AUTOSAR XML (schema 323)
package /Cluster
  can cluster CAN
    physical channel CAN
      frame FRAME_CommandModeControl: id 0xFFAB41, frame-length=8, can-addressing-mode=EXTENDED  # Operational commands are received by the module via control bits within this message.
        pdu PDU_CommandModeControl: length=64
          signal Enable_command: start 0, 2 bit, big-endian, data-type=DataType/Enable_command  # Run command. When set to a value of 'Enable', causes transition to grid forming or grid following mode depending on whether AC power is detected. Must be set to 'Disable' to leave POR or FAULTED state.
          signal FaultClear_command: start 2, 2 bit, big-endian, data-type=DataType/FaultClear_command  # Clears the latched fault message.
          signal InvertHwEnable_command: start 56, 2 bit, big-endian, data-type=DataType/InvertHwEnable_command  # Inverts the logic of the Hardware Enable input.
          signal EnableUPSMode_command: start 58, 2 bit, big-endian, data-type=DataType/EnableUPSMode_command  # Enables uninterruptible operation when transitioning from GRID FOLLOWING to GRID FORMING operation. If operating in GRID FOLLOWING mode, and AC grid voltage is interrupted, the module will transition to GRID FORMING mode, with no interruption in power.
          signal EnableSplitPhase_command: start 60, 2 bit, big-endian, data-type=DataType/EnableSplitPhase_command  # Dictates to the module whether it is connected to a three-phase (four wire) or split phase (L1, L2 and N) electrical system.
          signal ForceRelayMX1_command: start 32, 2 bit, big-endian, data-type=DataType/ForceRelayMX1_command  # If set to 'Force On,' will force the relay closed, overriding firmware state machine commands. Meant for diagnostic purposes only.
          signal ForceRelayMX2_command: start 34, 2 bit, big-endian, data-type=DataType/ForceRelayMX2_command  # If set to 'Force On,' will force the relay closed, overriding firmware state machine commands. Meant for diagnostic purposes only.
          signal ForceRelayK1_Precharge_command: start 36, 2 bit, big-endian, data-type=DataType/ForceRelayK1_Precharge_command  # If set to 'Force On,' will force the relay closed, overriding firmware state machine commands. Meant for diagnostic purposes only.
          signal ForceRelayRelayK2_DCRun_comand: start 38, 2 bit, big-endian, data-type=DataType/ForceRelayRelayK2_DCRun_comand  # If set to 'Force On,' will force the relay closed, overriding firmware state machine commands. Meant for diagnostic purposes only.
          signal PhaseRotation_command: start 62, 2 bit, big-endian, data-type=DataType/PhaseRotation_command  # Specifies phase rotation direction. Only active while transitioning from READY to GRID_FORMING
          signal MasterFollowerMode_command: start 16, 2 bit, big-endian, data-type=DataType/MasterFollowerMode_command  # Specifies what power command the inverter will follow in GRID FOLLOWING mode. When configured as Master, CommandPower will be used as the power command. When configured as Slave, the values in StatusMeasuredPower of the master inverter will be used.
      frame FRAME_CommandPower: id 0xCFFAC41, frame-length=8, can-addressing-mode=EXTENDED  # Sets the desired real (P) and reactive (Q) power levels for the module to follow while in the GRID FOLLOWING mode.
        pdu PDU_CommandPower: length=64
          signal RealPower command: start 24, 32 bit, big-endian, data-type=RealPower command  # Commanded real power (W) while in grid following mode - positive real power is defined as power being put into the ac network.
          signal ReactivePower_command: start 56, 32 bit, big-endian, data-type=DataType/ReactivePower_command  # Commanded reactive power (VA) while in grid following mode - positive reactive power is defined as the converter having a leading power factor.
      frame FRAME_CommandVF: id 0xCFFAE41, frame-length=8, can-addressing-mode=EXTENDED  # Sets the desired voltage and frequency for the module to produce while in the GRID FORMING mode. In addition, while in the READY and GRID FOLLOWING modes, this message is used to set the nominal voltage levels for detection of acceptable AC line voltage.
        pdu PDU_CommandVF: length=64
          signal Voltage_command: start 8, 16 bit, big-endian, data-type=DataType/Voltage_command  # Desired output voltage while in grid forming mode.
          signal Frequency_command: start 24, 16 bit, big-endian, data-type=DataType/Frequency_command  # Desired output frequency while in grid forming mode.
      frame FRAME_MasterMeasuredPower: id 0xCFFCAF6, frame-length=8, can-addressing-mode=EXTENDED  # Returns the actual measured power.
        pdu PDU_MasterMeasuredPower: length=64
          signal RealPower_measured: start 24, 32 bit, big-endian, data-type=DataType/RealPower_measured  # Measured real power.
          signal ReactivePower_measured: start 56, 32 bit, big-endian, data-type=DataType/ReactivePower_measured  # Measured reactive power.
      frame FRAME_CommandFactoryControl: id 0xCFFAF41, frame-length=8, can-addressing-mode=EXTENDED
        pdu PDU_CommandFactoryControl: length=64
          signal WriteSerialNumber: start 0, 2 bit, big-endian, data-type=WriteSerialNumber
          signal SerialNumber: start 56, 32 bit, big-endian, data-type=DataType/SerialNumber  # Serial number of the power module.
          signal FactoryAccess: start 24, 16 bit, big-endian, data-type=FactoryAccess
      frame FRAME_CommandSetNVParam: id 0xCFFAA41, frame-length=8, can-addressing-mode=EXTENDED  # Provides access to configure non-volatile parameters. Note that these parameters can only be set when the inverter's power stage is disabled (PowerCircuitEnabled_status in StatusBits message is 'Disabled.')
        pdu PDU_CommandSetNVParam: length=64
          signal CommandSetNVParam_MUX: start 8, 16 bit, big-endian, data-type=CommandSetNVParam_MUX
          signal Dummy: start 24, 16 bit, big-endian, data-type=DataType/Dummy
          signal VUnder50pct: start 24, 16 bit, big-endian, data-type=DataType/VUnder50pct
          signal V50to88pct: start 40, 16 bit, big-endian, data-type=DataType/V50to88pct
          signal V110to120pct: start 56, 16 bit, big-endian, data-type=DataType/V110to120pct
          signal VOver120: start 24, 16 bit, big-endian, data-type=DataType/VOver120
          signal FreqHi: start 24, 16 bit, big-endian, data-type=DataType/FreqHi
          signal FreqLo: start 40, 16 bit, big-endian, data-type=DataType/FreqLo
          signal FreqVeryLo: start 56, 16 bit, big-endian, data-type=DataType/FreqVeryLo
          signal FreqVeryLo: start 24, 16 bit, big-endian, data-type=DataType/FreqVeryLo
          signal FreqLo: start 40, 16 bit, big-endian, data-type=DataType/FreqLo
          signal FreqHi: start 56, 16 bit, big-endian, data-type=DataType/FreqHi
          signal NodeID: start 16, 8 bit, big-endian, data-type=NodeID  # J1939 Source Address node for the module.
          signal SA_Mask: start 24, 8 bit, big-endian, data-type=SA_Mask  # Not presently used.
          signal Baudrate: start 36, 4 bit, big-endian, data-type=Baudrate  # CAN baudrate
          signal ThermalOverload: start 16, 2 bit, big-endian, data-type=DataType/ThermalOverload
          signal MX1Open: start 24, 16 bit, big-endian, data-type=MX1Open  # Maximum time required for the MX1 contactor to open.
          signal MX1Close: start 40, 16 bit, big-endian, data-type=MX1Close  # Maximum time required for the MX1 contactor to close.
          signal MX2Open: start 56, 16 bit, big-endian, data-type=MX2Open  # Maximum time required for the MX2 contactor to open.
          signal MX2Close: start 24, 16 bit, big-endian, data-type=MX2Close  # Maximum time required for the MX2 contactor to open.
          signal K1Open: start 40, 16 bit, big-endian, data-type=K1Open  # Maximum time required for the K1 contactor to open.
          signal K1Close: start 56, 16 bit, big-endian, data-type=K1Close  # Maximum time required for the K1 contactor to close.
          signal K2Open: start 24, 16 bit, big-endian, data-type=K2Open  # Maximum time required for the K2 contactor to open.
          signal K2Close: start 40, 16 bit, big-endian, data-type=K2Close  # Maximum time required for the K2 contactor to close.
      frame FRAME_CommandModeControlAPU2: id 0xFF9B41, frame-length=8, can-addressing-mode=EXTENDED  # Operational commands are received by the module via control bits within this message.
        pdu PDU_CommandModeControlAPU2: length=64
          signal Enable_command: start 0, 2 bit, big-endian, data-type=DataType/Enable_command  # Run command. When set to a value of 'Enable', causes transition to grid forming or grid following mode depending on whether AC power is detected. Must be set to 'Disable' to leave POR or FAULTED state.
          signal FaultClear_command: start 2, 2 bit, big-endian, data-type=DataType/FaultClear_command  # Clears the latched fault message.
          signal InvertHwEnable_command: start 56, 2 bit, big-endian, data-type=DataType/InvertHwEnable_command  # Inverts the logic of the Hardware Enable input.
          signal EnableUPSMode_command: start 58, 2 bit, big-endian, data-type=DataType/EnableUPSMode_command  # Enables uninterruptible operation when transitioning from GRID FOLLOWING to GRID FORMING operation. If operating in GRID FOLLOWING mode, and AC grid voltage is interrupted, the module will transition to GRID FORMING mode, with no interruption in power.
          signal EnableSplitPhase_command: start 60, 2 bit, big-endian, data-type=DataType/EnableSplitPhase_command  # Dictates to the module whether it is connected to a three-phase (four wire) or split phase (L1, L2 and N) electrical system.
          signal ForceRelayMX1_command: start 32, 2 bit, big-endian, data-type=DataType/ForceRelayMX1_command  # If set to 'Force On,' will force the relay closed, overriding firmware state machine commands. Meant for diagnostic purposes only.
          signal ForceRelayMX2_command: start 34, 2 bit, big-endian, data-type=DataType/ForceRelayMX2_command  # If set to 'Force On,' will force the relay closed, overriding firmware state machine commands. Meant for diagnostic purposes only.
          signal ForceRelayK1_Precharge_command: start 36, 2 bit, big-endian, data-type=DataType/ForceRelayK1_Precharge_command  # If set to 'Force On,' will force the relay closed, overriding firmware state machine commands. Meant for diagnostic purposes only.
          signal ForceRelayRelayK2_DCRun_comand: start 38, 2 bit, big-endian, data-type=DataType/ForceRelayRelayK2_DCRun_comand  # If set to 'Force On,' will force the relay closed, overriding firmware state machine commands. Meant for diagnostic purposes only.
          signal PhaseRotation_command: start 62, 2 bit, big-endian, data-type=DataType/PhaseRotation_command  # Specifies phase rotation direction. Only active while transitioning from READY to GRID_FORMING
          signal MasterFollowerMode_command: start 16, 2 bit, big-endian, data-type=DataType/MasterFollowerMode_command  # Specifies what power command the inverter will follow in GRID FOLLOWING mode. When configured as Master, CommandPower will be used as the power command. When configured as Slave, the values in StatusMeasuredPower of the master inverter will be used.
      frame FRAME_CommandPowerAPU2: id 0xCFF9C41, frame-length=8, can-addressing-mode=EXTENDED  # Sets the desired real (P) and reactive (Q) power levels for the module to follow while in the GRID FOLLOWING mode.
        pdu PDU_CommandPowerAPU2: length=64
          signal RealPower_command: start 24, 32 bit, big-endian, data-type=RealPower_command  # Commanded real power (W) while in grid following mode - positive real power is defined as power being put into the ac network.
          signal ReactivePower_command: start 56, 32 bit, big-endian, data-type=DataType/ReactivePower_command  # Commanded reactive power (VA) while in grid following mode - positive reactive power is defined as the converter having a leading power factor.
      frame FRAME_CommandVFAPU2: id 0xCFF9E41, frame-length=8, can-addressing-mode=EXTENDED  # Sets the desired voltage and frequency for the module to produce while in the GRID FORMING mode. In addition, while in the READY and GRID FOLLOWING modes, this message is used to set the nominal voltage levels for detection of acceptable AC line voltage.
        pdu PDU_CommandVFAPU2: length=64
          signal Voltage_command: start 8, 16 bit, big-endian, data-type=DataType/Voltage_command  # Desired output voltage while in grid forming mode.
          signal Frequency_command: start 24, 16 bit, big-endian, data-type=DataType/Frequency_command  # Desired output frequency while in grid forming mode.
      frame FRAME_MasterMeasuredPowerAPU2: id 0xCFFCAF7, frame-length=8, can-addressing-mode=EXTENDED  # Returns the actual measured power.
        pdu PDU_MasterMeasuredPowerAPU2: length=64
          signal RealPower_measured: start 24, 32 bit, big-endian, data-type=DataType/RealPower_measured  # Measured real power.
          signal ReactivePower_measured: start 56, 32 bit, big-endian, data-type=DataType/ReactivePower_measured  # Measured reactive power.
      frame FRAME_justString: id 0x1CFFACC0, frame-length=8, can-addressing-mode=EXTENDED
        pdu PDU_justString: length=64
      frame FRAME_stringAndOther: id 0x1CFFABC0, frame-length=8, can-addressing-mode=EXTENDED
        pdu PDU_stringAndOther: length=64
          signal RealPower_measured: start 24, 32 bit, big-endian, data-type=DataType/RealPower_measured  # Measured real power.
      frame FRAME_StatusMeasuredPower: id 0xCFFCAF7, frame-length=8, can-addressing-mode=EXTENDED  # Returns the actual measured power.
        pdu PDU_StatusMeasuredPower: length=64
          signal RealPower_measured: start 24, 32 bit, big-endian, data-type=DataType/RealPower_measured  # Measured real power.
          signal ReactivePower_measured: start 56, 32 bit, big-endian, data-type=DataType/ReactivePower_measured  # Measured reactive power.
      frame FRAME_StatusCommandedPower: id 0x18FFC4F7, frame-length=8, can-addressing-mode=EXTENDED  # Echoes the commanded power (P&Q) as received in CommandPQ.
        pdu PDU_StatusCommandedPower: length=64
          signal RealPower_echo: start 24, 32 bit, big-endian, data-type=RealPower_echo  # Echoed real power command.
          signal ReactivePower_echo: start 56, 32 bit, big-endian, data-type=ReactivePower_echo  # Echoed reactive power command.
      frame FRAME_StatusBits: id 0xCFFC3F7, frame-length=8, can-addressing-mode=EXTENDED  # Bits representing the status of the power module.
        pdu PDU_StatusBits: length=64
          signal State_status: start 0, 4 bit, big-endian, data-type=State_status  # Active control mode.
          signal MX2Permissive_status: start 18, 2 bit, big-endian, data-type=MX2Permissive_status  # MX2 relay status
          signal PowerAvailAC_status: start 10, 2 bit, big-endian, data-type=PowerAvailAC_status  # Indicates that AC power is connected and that voltage and frequency are within nominal ranges.
          signal PowerAvailDC_status: start 12, 2 bit, big-endian, data-type=PowerAvailDC_status  # Indicates that DC bus voltage is within operating range.
          signal PowerCircuitEnabled_status: start 14, 2 bit, big-endian, data-type=PowerCircuitEnabled_status  # Indicates whether the switching devices are active.
          signal HardwareEnable_status: start 8, 2 bit, big-endian, data-type=HardwareEnable_status  # Status of the hardware enable.
          signal Enable_echo: start 4, 2 bit, big-endian, data-type=Enable_echo  # Echos the state of the Enable command withing the CommandModeControl message.
          signal FaultClr_echo: start 6, 2 bit, big-endian, data-type=FaultClr_echo  # Echos the state of the FaultClear command withing the CommandModeControl message.
          signal MessageValidModeControl_status: start 24, 2 bit, big-endian, data-type=MessageValidModeControl_status  # Indicates the validity of the CommandModeControl message. Message must be received at least once per second and parameter data within range to be considered valid.
          signal MX1Permissive_status: start 16, 2 bit, big-endian, data-type=MX1Permissive_status  # MX1 relay status
          signal K2DCRunPermissive_status: start 22, 2 bit, big-endian, data-type=K2DCRunPermissive_status  # K2 DC Run relay status.
          signal K1PrechargePermissive_status: start 20, 2 bit, big-endian, data-type=K1PrechargePermissive_status  # K1 precharge relay status.
          signal MessageValidPowerCMD_status: start 26, 2 bit, big-endian, data-type=MessageValidPowerCMD_status  # Indicates the validity of the CommandPQ message. Message must be received at least once per second and parameter data within range to be considered valid.
          signal MessageValidVF_status: start 28, 2 bit, big-endian, data-type=MessageValidVF_status  # Indicates the validity of the CommandVF message. Message must be received at least once per second and parameter data within range to be considered valid.
          signal CANbus_status: start 30, 2 bit, big-endian, data-type=CANbus_status  # Operational status of the CAN bus driver.
          signal EnableUPSMode_echo: start 32, 2 bit, big-endian, data-type=EnableUPSMode_echo  # Echos the state of the EnableUPSMode command withing the CommandModeControl message.
          signal EnableSplitPhase_echo: start 34, 2 bit, big-endian, data-type=EnableSplitPhase_echo  # Echos the state of the EnableSplitPhase command withing the CommandModeControl message.
          signal PhaseRotation_status: start 36, 2 bit, big-endian, data-type=PhaseRotation_status  # Phase rotation order. When L1 phase angle leads L2 phase angle, rotation is considered positive.
          signal LineVoltageDetected_status: start 38, 2 bit, big-endian, data-type=LineVoltageDetected_status  # Flag indicating if voltage is detected on L1, L2 or L3.
          signal PhaseRotation_echo: start 40, 2 bit, big-endian, data-type=PhaseRotation_echo  # Echos the state of PhaseRotation_command withing the CommandModeControl message.
      frame FRAME_StatusControlVoltage: id 0x1CFFC5F7, frame-length=8, can-addressing-mode=EXTENDED  # Lists present voltage of each power supply on the control board (24V, 15V, 5V, and 3.3V.)
        pdu PDU_StatusControlVoltage: length=64
          signal v5p0_Supply: start 8, 16 bit, big-endian, data-type=v5p0_Supply  # Present voltage of the control board 5V power suppy.
          signal v3p3_Supply: start 24, 16 bit, big-endian, data-type=v3p3_Supply  # Present voltage of the control board 3.3V power supply.
          signal v24_Supply: start 40, 16 bit, big-endian, data-type=v24_Supply  # Present voltage of the control board 24V power supply.
          signal v15_Supply: start 56, 16 bit, big-endian, data-type=v15_Supply  # Present voltage of the control board 15V power supply.
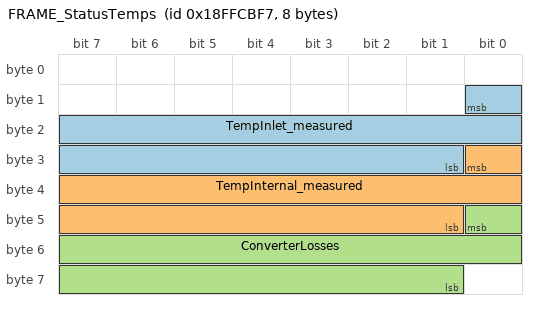
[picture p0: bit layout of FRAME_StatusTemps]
      frame FRAME_StatusTemps: id 0x18FFCBF7, frame-length=8, can-addressing-mode=EXTENDED  # Returns the inlet water temperature to the module as well as module internal ambient temperature.
        pdu PDU_StatusTemps: length=64
          signal TempInlet_measured: start 8, 16 bit, big-endian, data-type=TempInlet_measured  # Coolant inlet temperature
          signal TempInternal_measured: start 24, 16 bit, big-endian, data-type=TempInternal_measured  # Internal ambient temperature
          signal ConverterLosses: start 40, 16 bit, big-endian, data-type=ConverterLosses  # Power converter thermal loss
      frame FRAME_StatusFaults: id 0xCFFC8F7, frame-length=8, can-addressing-mode=EXTENDED  # Fault bits.
        pdu PDU_StatusFaults: length=64
          signal BridgeAVoltageOk_status: start 59, 1 bit, big-endian, data-type=BridgeAVoltageOk_status  # Indicates whether a hardware trip has been activated.
          signal OvercurrentAC_status: start 2, 2 bit, big-endian, data-type=OvercurrentAC_status  # Set immediately upon the software detection of AC current exceeding the threshold value.
          signal BridgeBVoltageOk_status: start 43, 1 bit, big-endian, data-type=BridgeBVoltageOk_status  # Indicates whether a hardware trip has been activated.
          signal OvervoltageDC_status: start 8, 2 bit, big-endian, data-type=OvervoltageDC_status  # Set immediately upon the software detection of DC voltage exceeding the threshold value.
          signal OvertempPowerDevice_status: start 14, 2 bit, big-endian, data-type=OvertempPowerDevice_status  # Set immediately upon the software detection of an IGBT temperature exceeding the threshold value.
          signal OvertempInternal_status: start 12, 2 bit, big-endian, data-type=OvertempInternal_status  # Set immediately upon the software detection of an internal inverter temperature exceeding the threshold value.
          signal LossValidControlMessage_status: start 20, 4 bit, big-endian, data-type=LossValidControlMessage_status  # Set whenever a control message required for operation contains out of range data or has not been received within the required timeout period.
          signal UndervoltageDC_status: start 10, 2 bit, big-endian, data-type=UndervoltageDC_status  # Indicates loss of DC source voltage.
          signal ControlHardwareFail_status: start 16, 4 bit, big-endian, data-type=ControlHardwareFail_status  # Set upon the failure of control hardware to return expected response.
          signal OvercurrentDC_status: start 6, 2 bit, big-endian, data-type=OvercurrentDC_status  # Set immediately upon the software detection of DC current exceeding the threshold value.
          signal GeneralFault_status: start 0, 2 bit, big-endian, data-type=GeneralFault_status  # Will be set any time a fault shutdown has occurred. It is always accompanied by an additional fault descriptor.
          signal LossOfAC_status: start 4, 2 bit, big-endian, data-type=LossOfAC_status  # In grid following mode, this fault will be triggered if AC voltage or frequency goes outside of nominal bounds and EnableUPSMode is not set in the CommandModeControl message.
          signal EStopShutdown_status: start 24, 2 bit, big-endian, data-type=EStopShutdown_status  # Set when an enable request has been sent whithout the WakeUpSignal flag (hardware enable) in the StatusBits message being active.
          signal BridgeAFault_status: start 56, 3 bit, big-endian, data-type=BridgeAFault_status  # Each bridge has hardware protection features as a backup to software protection. This bitfield indicates which, if any of these protection trips is active.
          signal BridgeBFault_status: start 40, 3 bit, big-endian, data-type=BridgeBFault_status  # Each bridge has hardware protection features as a backup to software protection. This bitfield indicates which, if any of these protection trips is active.
          signal IllegalTransition_status: start 26, 2 bit, big-endian, data-type=IllegalTransition_status  # Indicates that an illegal state transition was requested. For example, this fault will occur if Enable is commanded and line voltage is detected but AC power is not available.
          signal InvalidEEHeader_status: start 28, 2 bit, big-endian, data-type=InvalidEEHeader_status  # Indicates that reading of non-volatile parameters at power-up failed.
          signal InvalidEESection_status: start 30, 2 bit, big-endian, data-type=InvalidEESection_status  # Indicates that reading or writing of an non-volatile parameter section failed.
          signal ThermalOverload: start 32, 2 bit, big-endian, data-type=DataType/ThermalOverload
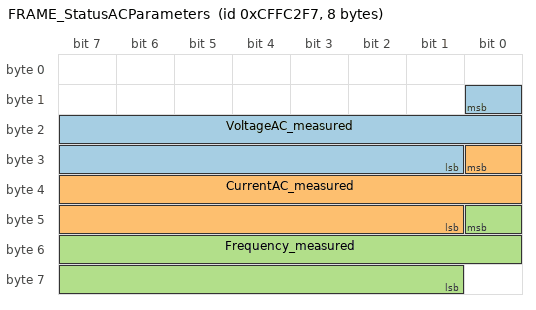
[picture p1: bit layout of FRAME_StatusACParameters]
      frame FRAME_StatusACParameters: id 0xCFFC2F7, frame-length=8, can-addressing-mode=EXTENDED  # RMS AC Voltage, current, and frequency measured by line A, B and C feedbacks.
        pdu PDU_StatusACParameters: length=64
          signal VoltageAC_measured: start 8, 16 bit, big-endian, data-type=VoltageAC_measured  # Measured RMS AC voltage.
          signal CurrentAC_measured: start 24, 16 bit, big-endian, data-type=CurrentAC_measured  # Measured RMS AC current.
          signal Frequency_measured: start 40, 16 bit, big-endian, data-type=Frequency_measured  # Measured frequency.
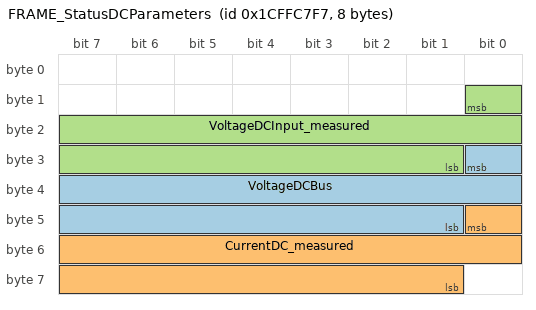
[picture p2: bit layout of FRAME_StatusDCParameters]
      frame FRAME_StatusDCParameters: id 0x1CFFC7F7, frame-length=8, can-addressing-mode=EXTENDED  # Measured (boosted) DC Bus voltage, DC Current, and estimated DC Input voltage.
        pdu PDU_StatusDCParameters: length=64
          signal VoltageDCBus: start 24, 16 bit, big-endian, data-type=VoltageDCBus  # Measured DC bus voltage.
          signal CurrentDC_measured: start 40, 16 bit, big-endian, data-type=CurrentDC_measured  # Measured DC current.
          signal VoltageDCInput_measured: start 8, 16 bit, big-endian, data-type=VoltageDCInput_measured  # Estimated DC input voltage.
      frame FRAME_StatusControlVolts2: id 0x1CFFC6F7, frame-length=8, can-addressing-mode=EXTENDED  # Present voltage of the -15V power supply on the control board.
        pdu PDU_StatusControlVolts2: length=64
          signal n15V_Supply: start 8, 16 bit, big-endian, data-type=n15V_Supply  # Present voltage of the control board -15V power supply.
          signal DiodeTemperature: start 40, 16 bit, big-endian, data-type=DiodeTemperature  # Hottest diode
          signal IGBTTemperature: start 56, 16 bit, big-endian, data-type=IGBTTemperature  # Hottest IGBT
      frame FRAME_softwareRev: id 0x1CFFC1F7, frame-length=8, can-addressing-mode=EXTENDED  # Software revision.
        pdu PDU_softwareRev: length=64
          signal InterfaceRev: start 24, 16 bit, big-endian, data-type=InterfaceRev  # Software revision of the CAN communication interface.
          signal ControlSwRev: start 8, 16 bit, big-endian, data-type=ControlSwRev  # Software revision of the control firmware.
          signal BuildTime: start 56, 32 bit, big-endian, data-type=BuildTime  # Build timestamp.
      frame FRAME_StatusCommandVF: id 0x18FFC9F7, frame-length=8, can-addressing-mode=EXTENDED  # Echoes the voltage and frequency commands from commandVF.
        pdu PDU_StatusCommandVF: length=64
          signal Voltage_echo: start 8, 16 bit, big-endian, data-type=Voltage_echo  # Echoed voltage command
          signal Frequency_echo: start 24, 16 bit, big-endian, data-type=Frequency_echo  # Echoed frequency command.
      frame FRAME_serialNumber: id 0x1CFFCCF7, frame-length=8, can-addressing-mode=EXTENDED  # Serial number of the power module.
        pdu PDU_serialNumber: length=64
          signal SerialNumber: start 24, 32 bit, big-endian, data-type=DataType/SerialNumber  # Serial number of the power module.
      frame FRAME_softwareRevHash: id 0x1CFFCDF7, frame-length=8, can-addressing-mode=EXTENDED  # Unique software revision identification hashcode.
        pdu PDU_softwareRevHash: length=64
          signal Hash: start 28, 28 bit, big-endian, data-type=Hash  # Unique revision identification hashcode.
      frame FRAME_StatusNVParam: id 0x1CFFA9F7, frame-length=8, can-addressing-mode=EXTENDED  # Echos back parameter values.
        pdu PDU_StatusNVParam: length=64
          signal StatusNVParam_MUX: start 8, 16 bit, big-endian, data-type=StatusNVParam_MUX
          signal Dummy: start 24, 16 bit, big-endian, data-type=DataType/Dummy
          signal VUnder50pct: start 24, 16 bit, big-endian, data-type=DataType/VUnder50pct
          signal V50to88pct: start 40, 16 bit, big-endian, data-type=DataType/V50to88pct
          signal V110to120pct: start 56, 16 bit, big-endian, data-type=DataType/V110to120pct
          signal VOver120: start 24, 16 bit, big-endian, data-type=DataType/VOver120
          signal FreqHi: start 24, 16 bit, big-endian, data-type=DataType/FreqHi
          signal FreqLo: start 40, 16 bit, big-endian, data-type=DataType/FreqLo
          signal FreqVeryLo: start 56, 16 bit, big-endian, data-type=DataType/FreqVeryLo
          signal FreqVeryLo: start 24, 16 bit, big-endian, data-type=DataType/FreqVeryLo
          signal FreqLo: start 40, 16 bit, big-endian, data-type=DataType/FreqLo
          signal FreqHi: start 56, 16 bit, big-endian, data-type=DataType/FreqHi
          signal StatusNodeID: start 16, 8 bit, big-endian, data-type=StatusNodeID  # J1939 Source Address node for the module
          signal StatusSA_Mask: start 24, 8 bit, big-endian, data-type=StatusSA_Mask  # Mask used to configure from which master source addresses to accept commands.
          signal StatusBaudrate: start 36, 4 bit, big-endian, data-type=StatusBaudrate
          signal StatusThermalOverload: start 16, 2 bit, big-endian, data-type=StatusThermalOverload  # Configured action to take when thermal overload input is active.
          signal StatusMX1Open: start 24, 16 bit, big-endian, data-type=StatusMX1Open  # Maximum time required for the MX1 contactor to open.
          signal StatusMX1Close: start 40, 16 bit, big-endian, data-type=StatusMX1Close  # Maximum time required for the MX1 contactor to close.
          signal StatusMX2Open: start 56, 16 bit, big-endian, data-type=StatusMX2Open  # Maximum time required for the MX2 contactor to open.
          signal StatusMX2Close: start 24, 16 bit, big-endian, data-type=StatusMX2Close  # Maximum time required for the MX2 contactor to open.
          signal StatusK1Open: start 40, 16 bit, big-endian, data-type=StatusK1Open  # Maximum time required for the K1 contactor to open.
          signal StatusK1Close: start 56, 16 bit, big-endian, data-type=StatusK1Close  # Maximum time required for the K1 contactor to close.
          signal StatusK2Open: start 24, 16 bit, big-endian, data-type=StatusK2Open  # Maximum time required for the K2 contactor to open.
          signal StatusK2Close: start 40, 16 bit, big-endian, data-type=StatusK2Close  # Maximum time required for the K2 contactor to close.
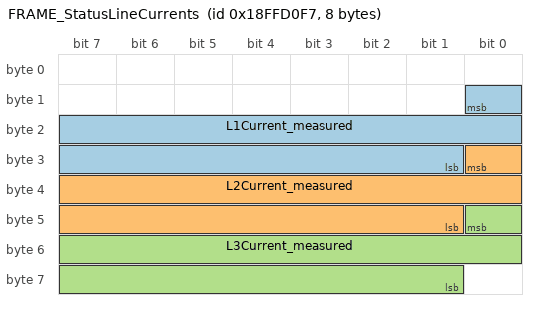
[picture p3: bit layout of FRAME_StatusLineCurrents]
      frame FRAME_StatusLineCurrents: id 0x18FFD0F7, frame-length=8, can-addressing-mode=EXTENDED  # Measured RMS line currents.
        pdu PDU_StatusLineCurrents: length=64
          signal L1Current_measured: start 8, 16 bit, big-endian, data-type=L1Current_measured  # Measured L1 RMS line current.
          signal L2Current_measured: start 24, 16 bit, big-endian, data-type=L2Current_measured  # Measured L2 RMS line current.
          signal L3Current_measured: start 40, 16 bit, big-endian, data-type=L3Current_measured  # Measured L3 RMS line current.
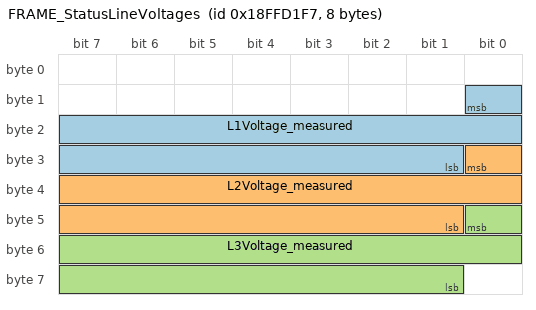
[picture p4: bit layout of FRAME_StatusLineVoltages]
      frame FRAME_StatusLineVoltages: id 0x18FFD1F7, frame-length=8, can-addressing-mode=EXTENDED  # Measured RMS line voltages.
        pdu PDU_StatusLineVoltages: length=64
          signal L1Voltage_measured: start 8, 16 bit, big-endian, data-type=L1Voltage_measured  # Measured L1 RMS line-neutral voltage
          signal L2Voltage_measured: start 24, 16 bit, big-endian, data-type=L2Voltage_measured  # Measured L2 RMS line-neutral voltage
          signal L3Voltage_measured: start 40, 16 bit, big-endian, data-type=L3Voltage_measured  # Measured L3 RMS line-neutral voltage
package /ISignal
  35 x i signal:
    Enable_command: system-signal=Signal/Enable_command
    FaultClear_command: system-signal=Signal/FaultClear_command
    InvertHwEnable_command: system-signal=Signal/InvertHwEnable_command
    EnableUPSMode_command: system-signal=Signal/EnableUPSMode_command
    EnableSplitPhase_command: system-signal=Signal/EnableSplitPhase_command
    ForceRelayMX1_command: system-signal=Signal/ForceRelayMX1_command
    ForceRelayMX2_command: system-signal=Signal/ForceRelayMX2_command
    ForceRelayK1_Precharge_command: system-signal=Signal/ForceRelayK1_Precharge_command
    ForceRelayRelayK2_DCRun_comand: system-signal=Signal/ForceRelayRelayK2_DCRun_comand
    PhaseRotation_command: system-signal=Signal/PhaseRotation_command
    MasterFollowerMode_command: system-signal=Signal/MasterFollowerMode_command
    ReactivePower_command: system-signal=Signal/ReactivePower_command
    Voltage_command: system-signal=Signal/Voltage_command
    Frequency_command: system-signal=Signal/Frequency_command
    RealPower_measured: system-signal=Signal/RealPower_measured
    ReactivePower_measured: system-signal=Signal/ReactivePower_measured
    SerialNumber: system-signal=Signal/SerialNumber
    Dummy: system-signal=Signal/Dummy
    VUnder50pct: system-signal=Signal/VUnder50pct
    V50to88pct: system-signal=Signal/V50to88pct
    V110to120pct: system-signal=Signal/V110to120pct
    VOver120: system-signal=Signal/VOver120
    FreqHi: system-signal=Signal/FreqHi
    FreqLo: system-signal=Signal/FreqLo
    FreqVeryLo: system-signal=Signal/FreqVeryLo
    FreqVeryLo: system-signal=Signal/FreqVeryLo
    FreqLo: system-signal=Signal/FreqLo
    FreqHi: system-signal=Signal/FreqHi
    ThermalOverload: system-signal=Signal/ThermalOverload
    RealPower_measured: system-signal=Signal/RealPower_measured
    ReactivePower_measured: system-signal=Signal/ReactivePower_measured
    RealPower_measured: system-signal=Signal/RealPower_measured
    FreqHi: system-signal=Signal/FreqHi
    FreqLo: system-signal=Signal/FreqLo
    FreqVeryLo: system-signal=Signal/FreqVeryLo
package /Signal
  35 x system signal:
    Enable_command: data-type=DataType/Enable_command, length=2  # Run command. When set to a value of 'Enable', causes transition to grid forming or grid following mode depending on whether AC power is detected. Must be set to 'Disable' to leave POR or FAULTED state.
    FaultClear_command: data-type=DataType/FaultClear_command, length=2  # Clears the latched fault message.
    InvertHwEnable_command: data-type=DataType/InvertHwEnable_command, length=2  # Inverts the logic of the Hardware Enable input.
    EnableUPSMode_command: data-type=DataType/EnableUPSMode_command, length=2  # Enables uninterruptible operation when transitioning from GRID FOLLOWING to GRID FORMING operation. If operating in GRID FOLLOWING mode, and AC grid voltage is interrupted, the module will transition to GRID FORMING mode, with no interruption in power.
    EnableSplitPhase_command: data-type=DataType/EnableSplitPhase_command, length=2  # Dictates to the module whether it is connected to a three-phase (four wire) or split phase (L1, L2 and N) electrical system.
    ForceRelayMX1_command: data-type=DataType/ForceRelayMX1_command, length=2  # If set to 'Force On,' will force the relay closed, overriding firmware state machine commands. Meant for diagnostic purposes only.
    ForceRelayMX2_command: data-type=DataType/ForceRelayMX2_command, length=2  # If set to 'Force On,' will force the relay closed, overriding firmware state machine commands. Meant for diagnostic purposes only.
    ForceRelayK1_Precharge_command: data-type=DataType/ForceRelayK1_Precharge_command, length=2  # If set to 'Force On,' will force the relay closed, overriding firmware state machine commands. Meant for diagnostic purposes only.
    ForceRelayRelayK2_DCRun_comand: data-type=DataType/ForceRelayRelayK2_DCRun_comand, length=2  # If set to 'Force On,' will force the relay closed, overriding firmware state machine commands. Meant for diagnostic purposes only.
    PhaseRotation_command: data-type=DataType/PhaseRotation_command, length=2  # Specifies phase rotation direction. Only active while transitioning from READY to GRID_FORMING.
    MasterFollowerMode_command: data-type=DataType/MasterFollowerMode_command, length=2  # Specifies what power command the inverter will follow in GRID FOLLOWING mode. When configured as Master, CommandPower will be used as the power command. When configured as Slave, the values in StatusMeasuredPower of the master inverter will be used.
    ReactivePower_command: data-type=DataType/ReactivePower_command, length=32  # Commanded reactive power (VA) while in grid following mode - positive reactive power is defined as the converter having a leading power factor.
    Voltage_command: data-type=DataType/Voltage_command, length=16  # Desired output voltage while in grid forming mode.
    Frequency_command: data-type=DataType/Frequency_command, length=16  # Desired output frequency while in grid forming mode.
    RealPower_measured: data-type=DataType/RealPower_measured, length=32  # Measured real power of master unit.
    ReactivePower_measured: data-type=DataType/ReactivePower_measured, length=32  # Measured reactive power of master unit.
    SerialNumber: data-type=DataType/SerialNumber, length=32
    Dummy: data-type=DataType/Dummy, length=16
    VUnder50pct: data-type=DataType/VUnder50pct, length=16  # Determines the fault trip time when Line-to-line rms voltage for a phase remains under 50 percent of the nominal value specified in the CommandVF message while the inverter is running in GRID FOLLOWING mode.
    V50to88pct: data-type=DataType/V50to88pct, length=16  # Determines the fault trip time when Line-to-line rms voltage for a phase remains between 50 and 88 percent of the nominal value specified in the CommandVF message while the inverter is running in GRID FOLLOWING mode.
    V110to120pct: data-type=DataType/V110to120pct, length=16  # Determines the fault trip time when Line-to-line rms voltage for a phase remains between 110 and 120 percent of the nominal value specified in the CommandVF message while the inverter is running in GRID FOLLOWING mode.
    VOver120: data-type=DataType/VOver120, length=16  # Determines the fault trip time when Line-to-line rms voltage for a phase remains Over 120 percent of the nominal value specified in the CommandVF message while the inverter is running in GRID FOLLOWING mode.
    FreqHi: data-type=DataType/FreqHi, length=16  # Determines the upper bound, above which the frequency monitor will trip if the line frequency remains for the time specified in FreqHi of the LFM_ClearingTimes Mux.
    FreqLo: data-type=DataType/FreqLo, length=16  # Determines the upper bound, in which the frequency monitor will trip if the line frequency remains below this bound but above the value of FreqVeryLo for the time specified in FreqLo of the LFM_ClearingTimes Mux.
    FreqVeryLo: data-type=DataType/FreqVeryLo, length=16  # Determines the upper bound, in which the frequency monitor will trip if the line frequency remains below this bound but above the value of FreqVeryLo for the time specified in FreqLo of the LFM_ClearingTimes Mux.
    FreqVeryLo: data-type=DataType/FreqVeryLo, length=16  # Determines the time it will take for a fault trip to occur when line frequency remains below the value specified in FreqVeryLo of the LFM_Limits Mux when the inverter is in GRID FOLLOWING mode.
    FreqLo: data-type=DataType/FreqLo, length=16  # Determines the time it will take for a fault trip to occur when line frequency remains between the value specified in FreqLo and FreqVeryLo of the LFM_Limits Mux when the inverter is in GRID FOLLOWING mode.
    FreqHi: data-type=DataType/FreqHi, length=16  # Determines the time it will take for a fault trip to occur when line frequency remains above the value specified in FreqHi of the LFM_Limits Mux when the inverter is in GRID FOLLOWING mode.
    ThermalOverload: data-type=DataType/ThermalOverload, length=2  # Configures action to take when thermal overload input is active.
    RealPower_measured: data-type=DataType/RealPower_measured, length=32  # Measured real power of master unit.
    ReactivePower_measured: data-type=DataType/ReactivePower_measured, length=32  # Measured reactive power of master unit.
    RealPower_measured: data-type=DataType/RealPower_measured, length=32  # Measured real power.
    FreqHi: data-type=DataType/FreqHi, length=16
    FreqLo: data-type=DataType/FreqLo, length=16
    FreqVeryLo: data-type=DataType/FreqVeryLo, length=16
package /DataType
  158 x integer type:
    Enable_command: compu {0=Disable, 1=Enable, 2=Error, 3=N/A, phys=raw}
    FaultClear_command: compu {0=Normal, 1=Clear Faults, 2=Error, 3=N/A, phys=raw}
    InvertHwEnable_command: compu {0=No invert, 1=Invert, 2=Error, 3=N/A, phys=raw}
    EnableUPSMode_command: compu {0=Disable, 1=Enable, 2=Error, 3=N/A, phys=raw}
    EnableSplitPhase_command: compu-method=Semantics/EnableSplitPhase_command
    ForceRelayMX1_command: compu {0=Normal, 1=Force On, 2=Error, 3=N/A, phys=raw}
    ForceRelayMX2_command: compu {0=Normal, 1=Force On, 2=Error, 3=N/A, phys=raw}
    ForceRelayK1_Precharge_command: compu {0=Normal, 1=Force On, 2=Error, 3=N/A, phys=raw}
    ForceRelayRelayK2_DCRun_comand: compu {0=Normal, 1=Force On, 2=Error, 3=N/A, phys=raw}
    PhaseRotation_command: compu {0=Negative, 1=Positive, 2=Error, 3=N/A, phys=raw}
    MasterFollowerMode_command: compu {0=Master, 1=Follower, 2=Error, 3=N/A, phys=raw}
    RealPower command: compu {phys=raw}
    ReactivePower_command: compu {phys=raw}
    Voltage_command: compu {phys=raw*0.1}
    Frequency_command: compu {phys=raw*0.1}
    RealPower_measured: compu {phys=raw}
    ReactivePower_measured: compu {phys=raw}
    WriteSerialNumber: compu {0=Disable, 1=Enable, 2=Error, 3=N/A, phys=raw}
    SerialNumber: compu {phys=raw}
    FactoryAccess: compu {phys=raw}
    CommandSetNVParam_MUX: compu {0=Param0, 1=LVM_ClearingTimes1, 2=LVM_ClearingTimes2, 3=LFM_Limits, 4=LFM_ClearingTimes, 5=J1939_Interface, 6=Fault_Config, 7=ContactorDelays1, 8=ContactorDelays2, 10=ContactorDelays3, phys=raw}
    Dummy: compu {phys=raw}
    VUnder50pct: compu {phys=raw}
    V50to88pct: compu {phys=raw}
    V110to120pct: compu {phys=raw}
    VOver120: compu {phys=raw}
    FreqHi: compu {phys=raw}
    FreqLo: compu {phys=raw}
    FreqVeryLo: compu {phys=raw}
    FreqVeryLo: compu {phys=raw}
    FreqLo: compu {phys=raw}
    FreqHi: compu {phys=raw}
    NodeID: compu {phys=raw}
    SA_Mask: compu {phys=raw}
    Baudrate: compu {0=125K, 1=250K, 2=500K, 3=1M, phys=raw}
    ThermalOverload: compu {0=Normal, 1=Fault Active, 2=Error, 3=N/A, phys=raw}
    MX1Open: compu {phys=raw}
    MX1Close: compu {phys=raw}
    MX2Open: compu {phys=raw}
    MX2Close: compu {phys=raw}
    K1Open: compu {phys=raw}
    K1Close: compu {phys=raw}
    K2Open: compu {phys=raw}
    K2Close: compu {phys=raw}
    Enable_command: compu {0=Disable, 1=Enable, 2=Error, 3=N/A, phys=raw}
    FaultClear_command: compu {0=Normal, 1=Clear Faults, 2=Error, 3=N/A, phys=raw}
    InvertHwEnable_command: compu {0=No invert, 1=Invert, 2=Error, 3=N/A, phys=raw}
    EnableUPSMode_command: compu {0=Disable, 1=Enable, 2=Error, 3=N/A, phys=raw}
    EnableSplitPhase_command: compu-method=Semantics/EnableSplitPhase_command
    ForceRelayMX1_command: compu {0=Normal, 1=Force On, 2=Error, 3=N/A, phys=raw}
    ForceRelayMX2_command: compu {0=Normal, 1=Force On, 2=Error, 3=N/A, phys=raw}
    ForceRelayK1_Precharge_command: compu {0=Normal, 1=Force On, 2=Error, 3=N/A, phys=raw}
    ForceRelayRelayK2_DCRun_comand: compu {0=Normal, 1=Force On, 2=Error, 3=N/A, phys=raw}
    PhaseRotation_command: compu {0=Negative, 1=Positive, 2=Error, 3=N/A, phys=raw}
    MasterFollowerMode_command: compu {0=Master, 1=Follower, 2=Error, 3=N/A, phys=raw}
    RealPower_command: compu {phys=raw}
    ReactivePower_command: compu {phys=raw}
    Voltage_command: compu {phys=raw*0.1}
    Frequency_command: compu {phys=raw*0.1}
    RealPower_measured: compu {phys=raw}
    ReactivePower_measured: compu {phys=raw}
    RealPower_measured: compu {phys=raw}
    RealPower_measured: compu {phys=raw}
    ReactivePower_measured: compu {phys=raw}
    RealPower_echo: compu {phys=raw}
    ReactivePower_echo: compu {phys=raw}
    State_status: compu {0=Power On Reset, and a quoted comma, 1=Ready, 2=Following, 3=Fault, 4=Forming, 5..15=N/A, phys=raw}
    MX2Permissive_status: compu {0=Open, 1=Closed, 2=Error, 3=N/A, phys=raw}
    PowerAvailAC_status: compu {0=None, 1=Available, 2=Error, 3=N/A, phys=raw}
    PowerAvailDC_status: compu {0=None, 1=Available, 2=Error, 3=N/A, phys=raw}
    PowerCircuitEnabled_status: compu {0=Disabled, 1=Enabled, 2=Error, 3=N/A, phys=raw}
    HardwareEnable_status: compu {0=Not Active, 1=Active, 2=Error, 3=N/A, phys=raw}
    Enable_echo: compu {0=Disable, 1=Enable, 2=Error, 3=N/A, phys=raw}
    FaultClr_echo: compu {0=Normal, 1=Clear Faults, 2=Error, 3=N/A, phys=raw}
    MessageValidModeControl_status: compu {0=Invalid, 1=Valid, 2=Error, 3=N/A, phys=raw}
    MX1Permissive_status: compu {0=Open, 1=Closed, 2=Error, 3=N/A, phys=raw}
    K2DCRunPermissive_status: compu {0=Open, 1=Closed, 2=Error, 3=N/A, phys=raw}
    K1PrechargePermissive_status: compu {0=Open, 1=Closed, 2=Error, 3=N/A, phys=raw}
    MessageValidPowerCMD_status: compu {0=Invalid, 1=Valid, 2=Error, 3=N/A, phys=raw}
    MessageValidVF_status: compu {0=Invalid, 1=Valid, 2=Error, 3=N/A, phys=raw}
    CANbus_status: compu {0=Normal, 1=Warning, 3=ErrorPassive, 4=N/A, phys=raw}
    EnableUPSMode_echo: compu {0=Disable, 1=Enable, 2=Error, 3=N/A, phys=raw}
    EnableSplitPhase_echo: compu {0=Normal - Three Phase Mode, 1=Enable Split Phase Mode, 2=Error, 3=N/A, phys=raw}
    PhaseRotation_status: compu {0=Negative, 1=Positive, 2=Error, 3=N/A, phys=raw}
    LineVoltageDetected_status: compu {0=No_Voltage, 1=Voltage_Detected, 2=Error, 3=N/A, phys=raw}
    PhaseRotation_echo: compu {0=Negative, 1=Positive, 2=Error, 3=N/A, phys=raw}
    v5p0_Supply: compu {phys=raw*0.01}
    v3p3_Supply: compu {phys=raw*0.01}
    v24_Supply: compu {phys=raw*0.01}
    v15_Supply: compu {phys=raw*0.01}
    TempInlet_measured: compu {phys=raw*0.1}
    TempInternal_measured: compu {phys=raw*0.1}
    ConverterLosses: compu {phys=raw}
    BridgeAVoltageOk_status: compu {0=Normal, 1=Fault Active, 2=Error, 3=N/A, phys=raw}
    OvercurrentAC_status: compu {0=Normal, 1=Fault Active, 2=Error, 3=N/A, phys=raw}
    BridgeBVoltageOk_status: compu {0=Normal, 1=Fault Active, 2=Error, 3=N/A, phys=raw}
    OvervoltageDC_status: compu {0=Normal, 1=Fault Active, 2=Error, 3=N/A, phys=raw}
    OvertempPowerDevice_status: compu {0=Normal, 1=Fault Active, 2=Error, 3=N/A, phys=raw}
    OvertempInternal_status: compu {0=Normal, 1=Fault Active, 2=Error, 3=N/A, phys=raw}
    LossValidControlMessage_status: compu {0=Normal, 1=Fault Active, 2=Error, 3=N/A, phys=raw}
    UndervoltageDC_status: compu {0=Normal, 1=Fault Active, 2=Error, 3=N/A, phys=raw}
    ControlHardwareFail_status: compu {0=Normal, 1=Fault Active, 2=Error, 3=N/A, phys=raw}
    OvercurrentDC_status: compu {0=Normal, 1=Fault Active, 2=Error, 3=N/A, phys=raw}
    GeneralFault_status: compu {0=Normal, 1=Fault Active, 2=Error, 3=N/A, phys=raw}
    LossOfAC_status: compu {0=Normal, 1=Fault Active, 2=Error, 3=N/A, phys=raw}
    EStopShutdown_status: compu {0=Normal, 1=Fault Active, 2=Error, 3=N/A, phys=raw}
    BridgeAFault_status: compu {0=Normal, 1=FLT_A, 2=N/A, 3=FLT_C, 4=OverVoltage, 5=FLT_B, 6=Overcurrent, 7=5V, phys=raw}
    BridgeBFault_status: compu {0=Normal, 1=FLT_A, 2=N/A, 3=FLT_C, 4=OverVoltage, 5=FLT_B, 6=Overcurrent, 7=5V, phys=raw}
    IllegalTransition_status: compu {0=Normal, 1=Fault Active, 2=Error, 3=N/A, phys=raw}
    InvalidEEHeader_status: compu {0=Normal, 1=Fault Active, 2=Error, 3=N/A, phys=raw}
    InvalidEESection_status: compu {0=Normal, 1=Fault Active, 2=Error, 3=N/A, phys=raw}
    ThermalOverload: compu {0=Normal, 1=Fault Active, 2=Error, 3=N/A, phys=raw}
    VoltageAC_measured: compu {phys=raw*0.1}
    CurrentAC_measured: compu {phys=raw}
    Frequency_measured: compu {phys=raw*0.1}
    VoltageDCBus: compu {phys=raw}
    CurrentDC_measured: compu {phys=raw}
    VoltageDCInput_measured: compu {phys=raw}
    n15V_Supply: compu {phys=raw*0.01}
    DiodeTemperature: compu {phys=raw}
    IGBTTemperature: compu {phys=raw}
    InterfaceRev: compu {phys=raw*0.01}
    ControlSwRev: compu {phys=raw*0.01}
    BuildTime: compu {phys=raw}
    Voltage_echo: compu {phys=raw*0.1}
    Frequency_echo: compu {phys=raw*0.1}
    SerialNumber: compu {phys=raw}
    Hash: compu {phys=raw}
    StatusNVParam_MUX: compu {0=ActParam0, 1=ActLVM_ClearingTimes1, 2=ActLVM_ClearingTimes2, 3=ActLFM_Limits, 4=ActLFM_ClearingTimes, 5=StatusJ1939_Interface, 6=StatusFault_Config, 7=StatusContactorDelays1, 8=StatusContactorDelays2, 9=StatusContactorDelays3, phys=raw}
    Dummy: compu {phys=raw}
    VUnder50pct: compu {phys=raw}
    V50to88pct: compu {phys=raw}
    V110to120pct: compu {phys=raw}
    VOver120: compu {phys=raw}
    FreqHi: compu {phys=raw}
    FreqLo: compu {phys=raw}
    FreqVeryLo: compu {phys=raw}
    FreqVeryLo: compu {phys=raw}
    FreqLo: compu {phys=raw}
    FreqHi: compu {phys=raw}
    StatusNodeID: compu {phys=raw}
    StatusSA_Mask: compu {phys=raw}
    StatusBaudrate: compu {0=125K, 1=250K, 2=500K, 3=1M, phys=raw}
    StatusThermalOverload: compu {0=Warning, 1=Fault, 2=Error, 3=N/A, phys=raw}
    StatusMX1Open: compu {phys=raw}
    StatusMX1Close: compu {phys=raw}
    StatusMX2Open: compu {phys=raw}
    StatusMX2Close: compu {phys=raw}
    StatusK1Open: compu {phys=raw}
    StatusK1Close: compu {phys=raw}
    StatusK2Open: compu {phys=raw}
    StatusK2Close: compu {phys=raw}
    L{1..3}Current_measured: compu {phys=raw}
    L{1..3}Voltage_measured: compu {phys=raw*0.1}
package /DataType/Semantics
  compu method Enable_command: 0=Disable, 1=Enable, 2=Error, 3=N/A, phys=raw
  compu method FaultClear_command: 0=Normal, 1=Clear Faults, 2=Error, 3=N/A, phys=raw
  compu method InvertHwEnable_command: 0=No invert, 1=Invert, 2=Error, 3=N/A, phys=raw
  compu method EnableUPSMode_command: 0=Disable, 1=Enable, 2=Error, 3=N/A, phys=raw
  compu method EnableSplitPhase_command: 0=Normal - Three Phase Mode, 1=Enable Split Phase Mode, 2=Error, 3=N/A, phys=raw
  compu method ForceRelayMX1_command: 0=Normal, 1=Force On, 2=Error, 3=N/A, phys=raw
  compu method ForceRelayMX2_command: 0=Normal, 1=Force On, 2=Error, 3=N/A, phys=raw
  compu method ForceRelayK1_Precharge_command: 0=Normal, 1=Force On, 2=Error, 3=N/A, phys=raw
  compu method ForceRelayRelayK2_DCRun_comand: 0=Normal, 1=Force On, 2=Error, 3=N/A, phys=raw
  compu method PhaseRotation_command: 0=Negative, 1=Positive, 2=Error, 3=N/A, phys=raw
  compu method MasterFollowerMode_command: 0=Master, 1=Follower, 2=Error, 3=N/A, phys=raw
  compu method ReactivePower_command: phys=raw
  compu method Voltage_command: phys=raw*0.1
  compu method Frequency_command: phys=raw*0.1
  compu method RealPower_measured: phys=raw
  compu method ReactivePower_measured: phys=raw
  compu method SerialNumber: phys=raw
  compu method Dummy: phys=raw
  compu method VUnder50pct: phys=raw
  compu method V50to88pct: phys=raw
  compu method V110to120pct: phys=raw
  compu method VOver120: phys=raw
  compu method FreqHi: phys=raw*0.1
  compu method FreqLo: phys=raw*0.1
  compu method FreqVeryLo: phys=raw*0.1
  compu method FreqVeryLo: phys=raw
  compu method FreqLo: phys=raw
  compu method FreqHi: phys=raw
  compu method ThermalOverload: 0=Warning, 1=Fault, 2=Error, 3=N/A, phys=raw
  compu method EnableSplitPhase_command: 0=Normal - Three Phase Mode, 1=Enable Split Phase Mode, 2=Error, 3=N/A, phys=raw
  compu method RealPower_measured: phys=raw
  compu method ReactivePower_measured: phys=raw
  compu method RealPower_measured: phys=raw
  compu method FreqHi: phys=raw*0.1
  compu method FreqLo: phys=raw*0.1
  compu method FreqVeryLo: phys=raw*0.1
package /DataType/Unit
  158 x unit:
    Enable_command
    FaultClear_command
    InvertHwEnable_command
    EnableUPSMode_command
    EnableSplitPhase_command
    ForceRelayMX1_command
    ForceRelayMX2_command
    ForceRelayK1_Precharge_command
    ForceRelayRelayK2_DCRun_comand
    PhaseRotation_command
    MasterFollowerMode_command
    RealPower command: display-name=W
    ReactivePower_command: display-name=VA
    Voltage_command: display-name=Vrms
    Frequency_command: display-name=Hz
    RealPower_measured: display-name=W
    ReactivePower_measured: display-name=VA
    WriteSerialNumber
    SerialNumber
    FactoryAccess
    CommandSetNVParam_MUX
    Dummy
    VUnder50pct: display-name=ms
    V50to88pct: display-name=ms
    V110to120pct: display-name=ms
    VOver120
    FreqHi: display-name=Hz
    FreqLo: display-name=Hz
    FreqVeryLo: display-name=Hz
    FreqVeryLo: display-name=ms
    FreqLo: display-name=ms
    FreqHi: display-name=ms
    NodeID
    SA_Mask
    Baudrate
    ThermalOverload
    MX1Open: display-name=ms
    MX1Close: display-name=ms
    MX2Open: display-name=ms
    MX2Close: display-name=ms
    K1Open: display-name=ms
    K1Close: display-name=ms
    K2Open: display-name=ms
    K2Close: display-name=ms
    Enable_command
    FaultClear_command
    InvertHwEnable_command
    EnableUPSMode_command
    EnableSplitPhase_command
    ForceRelayMX1_command
    ForceRelayMX2_command
    ForceRelayK1_Precharge_command
    ForceRelayRelayK2_DCRun_comand
    PhaseRotation_command
    MasterFollowerMode_command
    RealPower_command: display-name=W
    ReactivePower_command: display-name=VA
    Voltage_command: display-name=Vrms
    Frequency_command: display-name=Hz
    RealPower_measured: display-name=W
    ReactivePower_measured: display-name=VA
    RealPower_measured: display-name=W
    RealPower_measured: display-name=W
    ReactivePower_measured: display-name=VA
    RealPower_echo: display-name=W
    ReactivePower_echo: display-name=VA
    State_status
    MX2Permissive_status
    PowerAvailAC_status
    PowerAvailDC_status
    PowerCircuitEnabled_status
    HardwareEnable_status
    Enable_echo
    FaultClr_echo
    MessageValidModeControl_status
    MX1Permissive_status
    K2DCRunPermissive_status
    K1PrechargePermissive_status
    MessageValidPowerCMD_status
    MessageValidVF_status
    CANbus_status
    EnableUPSMode_echo
    EnableSplitPhase_echo
    PhaseRotation_status
    LineVoltageDetected_status
    PhaseRotation_echo
    v5p0_Supply: display-name=V
    v3p3_Supply: display-name=V
    v24_Supply: display-name=V
    v15_Supply: display-name=V
    TempInlet_measured: display-name=C
    TempInternal_measured: display-name=C
    ConverterLosses: display-name=W
    BridgeAVoltageOk_status
    OvercurrentAC_status
    BridgeBVoltageOk_status
    OvervoltageDC_status
    OvertempPowerDevice_status
    OvertempInternal_status
    LossValidControlMessage_status
    UndervoltageDC_status
    ControlHardwareFail_status
    OvercurrentDC_status
    GeneralFault_status
    LossOfAC_status
    EStopShutdown_status
    BridgeAFault_status
    BridgeBFault_status
    IllegalTransition_status
    InvalidEEHeader_status
    InvalidEESection_status
    ThermalOverload
    VoltageAC_measured: display-name=V
    CurrentAC_measured: display-name=A
    Frequency_measured: display-name=Hz
    VoltageDCBus: display-name=V
    CurrentDC_measured: display-name=A
    VoltageDCInput_measured: display-name=V
    n15V_Supply: display-name=V
    DiodeTemperature: display-name=C
    IGBTTemperature: display-name=C
    InterfaceRev
    ControlSwRev
    BuildTime
    Voltage_echo: display-name=Vrms
    Frequency_echo: display-name=Hz
    SerialNumber
    Hash
    StatusNVParam_MUX
    Dummy
    VUnder50pct: display-name=ms
    V50to88pct: display-name=ms
    V110to120pct: display-name=ms
    VOver120
    FreqHi: display-name=Hz
    FreqLo: display-name=Hz
    FreqVeryLo: display-name=Hz
    FreqVeryLo: display-name=ms
    FreqLo: display-name=ms
    FreqHi: display-name=ms
    StatusNodeID
    StatusSA_Mask
    StatusBaudrate
    StatusThermalOverload
    StatusMX1Open: display-name=ms
    StatusMX1Close: display-name=ms
    StatusMX2Open: display-name=ms
    StatusMX2Close: display-name=ms
    StatusK1Open: display-name=ms
    StatusK1Close: display-name=ms
    StatusK2Open: display-name=ms
    StatusK2Close: display-name=ms
    L{1..3}Current_measured: display-name=A
    L{1..3}Voltage_measured: display-name=Vrms
